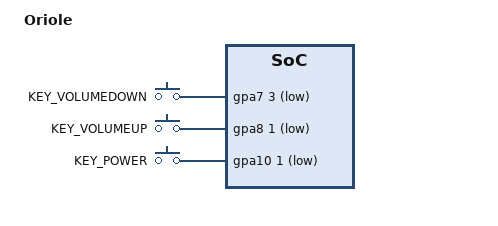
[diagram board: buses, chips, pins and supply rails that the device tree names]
// SPDX-License-Identifier: GPL-2.0-only
/*
 * Oriole Device Tree
 *
 * Copyright 2021-2023 Google,LLC
 */

/dts-v1/;
/plugin/;

#include <dt-bindings/gpio/gpio.h>
#include <dt-bindings/input/input.h>
#include "gs101-pinctrl.h"
#include "gs101.dtsi"

/ {
	model = "Oriole";
	compatible = "google,gs101-oriole", "google,gs101";

	chosen {
		bootargs = "earlycon=exynos4210,mmio32,0x10A00000 console=ttySAC0";
	};

	gpio-keys {
		compatible = "gpio-keys";
		pinctrl-names = "default";
		pinctrl-0 = <&key_voldown &key_volup &key_power>;

		button-vol-down {
			label = "KEY_VOLUMEDOWN";
			linux,code = <KEY_VOLUMEDOWN>;
			gpios = <&gpa7 3 GPIO_ACTIVE_LOW>;
			wakeup-source;
		};

		button-vol-up {
			label = "KEY_VOLUMEUP";
			linux,code = <KEY_VOLUMEUP>;
			gpios = <&gpa8 1 GPIO_ACTIVE_LOW>;
			wakeup-source;
		};

		button-power {
			label = "KEY_POWER";
			linux,code = <KEY_POWER>;
			gpios = <&gpa10 1 GPIO_ACTIVE_LOW>;
			wakeup-source;
		};
	};
};

&pinctrl_1 {
	key_voldown: key-voldown-pins {
		samsung,pins = "gpa7-3";
		samsung,pin-function = <0xf>;
		samsung,pin-pud = <0>;
		samsung,pin-drv = <GS101_PIN_DRV_2_5_MA>;
	};

	key_volup: key-volup-pins {
		samsung,pins = "gpa8-1";
		samsung,pin-function = <0xf>;
		samsung,pin-pud = <0>;
		samsung,pin-drv = <GS101_PIN_DRV_2_5_MA>;
	};
};

&pinctrl_0 {
	key_power: key-power-pins {
		samsung,pins = "gpa10-1";
		samsung,pin-function = <0xf>;
		samsung,pin-pud = <0>;
		samsung,pin-drv = <GS101_PIN_DRV_2_5_MA>;
	};
};

&watchdog_cl0 {
	timeout-sec = <30>;
};
